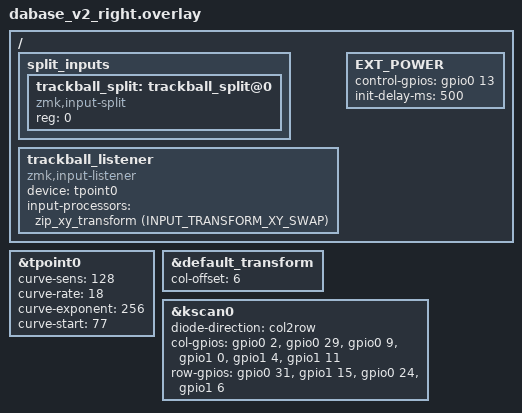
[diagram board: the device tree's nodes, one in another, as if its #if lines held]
/*
 * Copyright (c) 2020 The ZMK Contributors
 *
 * SPDX-License-Identifier: MIT
 *
 * Exp69 fresh: direct PS/2 trackpoint (gpio-ps2) on the right half —
 * no ATtiny/Pro Mini coprocessor. See dabase-v2-right-ps2.dtsi.
 */

#include "dabase_v2.dtsi"
#include "dabase-v2-right-ps2.dtsi"
#include <dt-bindings/zmk/keys.h>
#include <behaviors.dtsi>

/* Exp74: on-device PowerCurve (RawAccel-style, ported from the AVR library).
 * Same tuning as the coprocessor era (Exp60/61 known-good): sens 0.5x,
 * rate 0.070, exp 1.0, start 0.30 -> slow nudge < 1x gain (precise crawl),
 * fast flick > 1x. curve-rate != 0 = curve enabled (driver default is off).
 * Tuning = edit these, rebuild the right half, flash (like the old I2C path). */
&tpoint0 {
    curve-sens = <128>;
    curve-rate = <18>;
    curve-exponent = <256>;
    curve-start = <77>;
};

/* Exp71: direction fix - the TP's sensor axes are rotated vs the mount
 * (nub up -> cursor left, nub left -> cursor up). Apply the inverse in
 * software. Iteration 1 was swap+invert-both (=7) which OVER-corrected
 * (up->down, left->right): this TP's raw/screen sign convention already
 * matches, so the correction is SWAP ONLY. The TP rejects host commands,
 * so its register invert/swap bits are no-ops. The transform runs on the
 * right half before split-forward (peripheral) or before HID
 * (standalone-central listener).
 */
#include <input/processors.dtsi>
#include <dt-bindings/zmk/input_transform.h>

&default_transform {
    col-offset = <6>;
};

&kscan0 {
    diode-direction = "col2row";
    col-gpios
        = <&gpio0 2  GPIO_ACTIVE_HIGH>
        , <&gpio0 29 GPIO_ACTIVE_HIGH>
        , <&gpio0 9  GPIO_ACTIVE_HIGH>
        , <&gpio1 0  GPIO_ACTIVE_HIGH>
        , <&gpio1 4  GPIO_ACTIVE_HIGH>
        , <&gpio1 11 GPIO_ACTIVE_HIGH>
    ;

    row-gpios
        = <&gpio0 31 (GPIO_ACTIVE_HIGH | GPIO_PULL_DOWN)>
        , <&gpio1 15 (GPIO_ACTIVE_HIGH | GPIO_PULL_DOWN)>
        , <&gpio0 24 (GPIO_ACTIVE_HIGH | GPIO_PULL_DOWN)>
        , <&gpio1 6  (GPIO_ACTIVE_HIGH | GPIO_PULL_DOWN)>
    ;
};

/ {
    split_inputs {
        #address-cells = <1>;
        #size-cells = <0>;

        trackball_split: trackball_split@0 {
            compatible = "zmk,input-split";
            reg = <0>;
        };
    };

    trackball_listener: trackball_listener {
        compatible = "zmk,input-listener";
        status = "disabled";
        device = <&tpoint0>;
    };
};

#ifdef CONFIG_ZMK_SPLIT_ROLE_CENTRAL
/* standalone USB right half (or local central): listen to the direct-PS2 TP */
&trackball_listener {
    status = "okay";
    input-processors = <&zip_xy_transform (INPUT_TRANSFORM_XY_SWAP)>;
};
#else
/* BLE peripheral: forward direct-PS2 input to the central (dongle).
 * The split node runs its input-processors BEFORE forwarding, so the
 * corrected events land on the dongle (no dongle-side change needed). */
&trackball_split {
    device = <&tpoint0>;
    input-processors = <&zip_xy_transform (INPUT_TRANSFORM_XY_SWAP)>;
};
#endif

/ {
    EXT_POWER {
        /* nice_nano EXT_VCC rail — powers the trackpoint directly (3.3V) */
        control-gpios = <&gpio0 13 GPIO_ACTIVE_HIGH>;
        init-delay-ms = <500>;
    };
};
